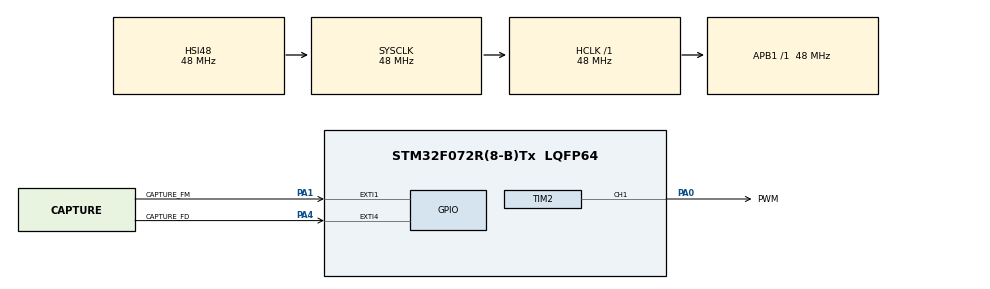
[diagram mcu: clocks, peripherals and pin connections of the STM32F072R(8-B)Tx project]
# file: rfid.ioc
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Mcu.Family=STM32F0
Mcu.Name=STM32F072R(8-B)Tx
Mcu.Package=LQFP64
NVIC.EXTI0_1_IRQn=true\:0\:0\:false\:false\:true\:true
NVIC.EXTI4_15_IRQn=true\:0\:0\:false\:false\:true\:true
NVIC.TIM17_IRQn=true\:0\:0\:false\:false\:true\:true
PA0.GPIO_Label=PWM
PA0.Signal=S_TIM2_CH1_ETR
PA1.GPIO_Label=CAPTURE_FM
PA1.GPIO_ModeDefaultEXTI=GPIO_MODE_IT_RISING
PA1.Signal=GPXTI1
PA4.GPIO_Label=CAPTURE_FD
PA4.GPIO_ModeDefaultEXTI=GPIO_MODE_IT_FALLING
PA4.Signal=GPXTI4
ProjectManager.HeapSize=0x200
ProjectManager.StackSize=0x400
ProjectManager.TargetToolchain=TrueSTUDIO
RCC.AHBFreq_Value=48000000
RCC.APB1Freq_Value=48000000
RCC.APB1TimFreq_Value=48000000
RCC.HCLKFreq_Value=48000000
RCC.SYSCLKFreq_VALUE=48000000
RCC.SYSCLKSource=RCC_SYSCLKSOURCE_HSI48
SH.S_TIM2_CH1_ETR.0=TIM2_CH1,PWM Generation1 CH1
TIM17.Prescaler=48000
TIM2.Channel-PWM\ Generation1\ CH1=TIM_CHANNEL_1
VP_TIM16_VS_ClockSourceINT.Mode=Enable_Timer
VP_TIM17_VS_ClockSourceINT.Mode=Enable_Timer
VP_TIM2_VS_ClockSourceINT.Mode=Internal
VP_TIM7_VS_ClockSourceINT.Mode=Enable_Timer
board=rfid

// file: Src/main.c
/**
  ******************************************************************************
  * @file           : main.c
  * @brief          : Main program body
  ******************************************************************************
  ** This notice applies to any and all portions of this file
  * that are not between comment pairs USER CODE BEGIN and
  * USER CODE END. Other portions of this file, whether
  * inserted by the user or by software development tools
  * are owned by their respective copyright owners.
  *
  * COPYRIGHT(c) 2020 STMicroelectronics
  *
  * Redistribution and use in source and binary forms, with or without modification,
  * are permitted provided that the following conditions are met:
  *   1. Redistributions of source code must retain the above copyright notice,
  *      this list of conditions and the following disclaimer.
  *   2. Redistributions in binary form must reproduce the above copyright notice,
  *      this list of conditions and the following disclaimer in the documentation
  *      and/or other materials provided with the distribution.
  *   3. Neither the name of STMicroelectronics nor the names of its contributors
  *      may be used to endorse or promote products derived from this software
  *      without specific prior written permission.
  *
  * THIS SOFTWARE IS PROVIDED BY THE COPYRIGHT HOLDERS AND CONTRIBUTORS "AS IS"
  * AND ANY EXPRESS OR IMPLIED WARRANTIES, INCLUDING, BUT NOT LIMITED TO, THE
  * IMPLIED WARRANTIES OF MERCHANTABILITY AND FITNESS FOR A PARTICULAR PURPOSE ARE
  * DISCLAIMED. IN NO EVENT SHALL THE COPYRIGHT HOLDER OR CONTRIBUTORS BE LIABLE
  * FOR ANY DIRECT, INDIRECT, INCIDENTAL, SPECIAL, EXEMPLARY, OR CONSEQUENTIAL
  * DAMAGES (INCLUDING, BUT NOT LIMITED TO, PROCUREMENT OF SUBSTITUTE GOODS OR
  * SERVICES; LOSS OF USE, DATA, OR PROFITS; OR BUSINESS INTERRUPTION) HOWEVER
  * CAUSED AND ON ANY THEORY OF LIABILITY, WHETHER IN CONTRACT, STRICT LIABILITY,
  * OR TORT (INCLUDING NEGLIGENCE OR OTHERWISE) ARISING IN ANY WAY OUT OF THE USE
  * OF THIS SOFTWARE, EVEN IF ADVISED OF THE POSSIBILITY OF SUCH DAMAGE.
  *
  ******************************************************************************
  */
#include "main.h"
#include "stm32f0xx_hal.h"

TIM_HandleTypeDef htim2;
TIM_HandleTypeDef htim7;
TIM_HandleTypeDef htim16;
TIM_HandleTypeDef htim17;

/* USER CODE BEGIN PV */
/* Private variables ---------------------------------------------------------*/
volatile int flag_front_montant = 0;
volatile int flag_front_descendant = 0;
volatile int FLAG_TRAME_OK = 0;
volatile int FLAG_HORLOGE_OK = 0;
volatile int COUNT_DONNEES_DEBUT = 0;
volatile int COUNT_DONNEES_FIN = 0;
volatile int NB_US = 0;
volatile int TRAME[64];

// Configurations et calibrations
const volatile int tolerance = 5;

/* USER CODE END PV */

void SystemClock_Config(void);
static void MX_GPIO_Init(void);
static void MX_TIM17_Init(void);
static void MX_TIM16_Init(void);
static void MX_TIM2_Init(void);
static void MX_TIM7_Init(void);
void HAL_TIM_MspPostInit(TIM_HandleTypeDef *htim);

/* USER CODE BEGIN PFP */
/* Private function prototypes -----------------------------------------------*/

/* USER CODE END PFP */

int main(void)
{

  /* MCU Configuration----------------------------------------------------------*/

  /* Reset of all peripherals, Initializes the Flash interface and the Systick. */
  HAL_Init();

  /* Configure the system clock */
  SystemClock_Config();

  /* Initialize all configured peripherals */
  MX_GPIO_Init();
  MX_TIM17_Init();
  MX_TIM16_Init();
  MX_TIM2_Init();
  MX_TIM7_Init();
  /* USER CODE BEGIN 2 */
  HAL_TIM_Base_Start_IT(&htim17);
  /* USER CODE END 2 */

  /* Infinite loop */
  /* USER CODE BEGIN WHILE */
  while (1)
  {
	  if (flag_front_descendant == 1){
		    flag_front_descendant = 0;

			if (FLAG_HORLOGE_OK == 0){
				TIM17->CR1 &= 0;

				TIM17->CR1 |= (1<<0);
				NVIC_EnableIRQ(TIM17_IRQn);
			}
			else if (FLAG_HORLOGE_OK == 1) {

				if (COUNT_DONNEES_DEBUT >= 9){
					TIM17->CR1 &= 0;

					if (512 - tolerance <= NB_US && NB_US >= 512 + tolerance){
						COUNT_DONNEES_DEBUT++;

						// Remplir le tableau de donnees -- 0
						TRAME[COUNT_DONNEES_DEBUT - 10] = 0;

						COUNT_DONNEES_FIN = 0;
					}
					else{
						FLAG_HORLOGE_OK = 0;
					}

					TIM17->CR1 |= (1<<0);
					NVIC_EnableIRQ(TIM17_IRQn);

				}
			}

	  }

	  if (flag_front_montant == 1){
		    flag_front_montant = 0;

			TIM17->CR1 &= 0;

			if (512 - tolerance <= NB_US && NB_US >= 512 + tolerance){
				if (FLAG_HORLOGE_OK == 0){
					FLAG_HORLOGE_OK = 1;
					COUNT_DONNEES_DEBUT++;
				}
				else if(FLAG_HORLOGE_OK == 1){
					COUNT_DONNEES_DEBUT++;

					if (COUNT_DONNEES_DEBUT > 9){
						// Remplir tableau de donnees -- 1
						TRAME[COUNT_DONNEES_DEBUT - 10] = 1;

						COUNT_DONNEES_DEBUT++;
						COUNT_DONNEES_FIN++;

						if (COUNT_DONNEES_FIN == 9){
							// On traite la trame reçu

							FLAG_TRAME_OK = 1;
						}
					}
				}
			}
			else{
				FLAG_HORLOGE_OK = 0;
			}

			TIM17->CR1 |= (1<<0);
			NVIC_EnableIRQ(TIM17_IRQn);
	  }
  /* USER CODE END WHILE */

  }

}

void SystemClock_Config(void)
{

  RCC_OscInitTypeDef RCC_OscInitStruct;
  RCC_ClkInitTypeDef RCC_ClkInitStruct;

    /**Initializes the CPU, AHB and APB busses clocks
    */
  RCC_OscInitStruct.OscillatorType = RCC_OSCILLATORTYPE_HSI48;
  RCC_OscInitStruct.HSI48State = RCC_HSI48_ON;
  RCC_OscInitStruct.PLL.PLLState = RCC_PLL_NONE;
  if (HAL_RCC_OscConfig(&RCC_OscInitStruct) != HAL_OK)
  {
    _Error_Handler(__FILE__, __LINE__);
  }

    /**Initializes the CPU, AHB and APB busses clocks
    */
  RCC_ClkInitStruct.ClockType = RCC_CLOCKTYPE_HCLK|RCC_CLOCKTYPE_SYSCLK
                              |RCC_CLOCKTYPE_PCLK1;
  RCC_ClkInitStruct.SYSCLKSource = RCC_SYSCLKSOURCE_HSI48;
  RCC_ClkInitStruct.AHBCLKDivider = RCC_SYSCLK_DIV1;
  RCC_ClkInitStruct.APB1CLKDivider = RCC_HCLK_DIV1;

  if (HAL_RCC_ClockConfig(&RCC_ClkInitStruct, FLASH_LATENCY_1) != HAL_OK)
  {
    _Error_Handler(__FILE__, __LINE__);
  }

    /**Configure the Systick interrupt time
    */
  HAL_SYSTICK_Config(HAL_RCC_GetHCLKFreq()/1000);

    /**Configure the Systick
    */
  HAL_SYSTICK_CLKSourceConfig(SYSTICK_CLKSOURCE_HCLK);

  /* SysTick_IRQn interrupt configuration */
  HAL_NVIC_SetPriority(SysTick_IRQn, 0, 0);
}

/* TIM2 init function */
static void MX_TIM2_Init(void)
{

  TIM_ClockConfigTypeDef sClockSourceConfig;
  TIM_MasterConfigTypeDef sMasterConfig;
  TIM_OC_InitTypeDef sConfigOC;

  htim2.Instance = TIM2;
  htim2.Init.Prescaler = 0;
  htim2.Init.CounterMode = TIM_COUNTERMODE_UP;
  htim2.Init.Period = 0;
  htim2.Init.ClockDivision = TIM_CLOCKDIVISION_DIV1;
  htim2.Init.AutoReloadPreload = TIM_AUTORELOAD_PRELOAD_DISABLE;
  if (HAL_TIM_Base_Init(&htim2) != HAL_OK)
  {
    _Error_Handler(__FILE__, __LINE__);
  }

  sClockSourceConfig.ClockSource = TIM_CLOCKSOURCE_INTERNAL;
  if (HAL_TIM_ConfigClockSource(&htim2, &sClockSourceConfig) != HAL_OK)
  {
    _Error_Handler(__FILE__, __LINE__);
  }

  if (HAL_TIM_PWM_Init(&htim2) != HAL_OK)
  {
    _Error_Handler(__FILE__, __LINE__);
  }

  sMasterConfig.MasterOutputTrigger = TIM_TRGO_RESET;
  sMasterConfig.MasterSlaveMode = TIM_MASTERSLAVEMODE_DISABLE;
  if (HAL_TIMEx_MasterConfigSynchronization(&htim2, &sMasterConfig) != HAL_OK)
  {
    _Error_Handler(__FILE__, __LINE__);
  }

  sConfigOC.OCMode = TIM_OCMODE_PWM1;
  sConfigOC.Pulse = 0;
  sConfigOC.OCPolarity = TIM_OCPOLARITY_HIGH;
  sConfigOC.OCFastMode = TIM_OCFAST_DISABLE;
  if (HAL_TIM_PWM_ConfigChannel(&htim2, &sConfigOC, TIM_CHANNEL_1) != HAL_OK)
  {
    _Error_Handler(__FILE__, __LINE__);
  }

  HAL_TIM_MspPostInit(&htim2);

}

/* TIM7 init function */
static void MX_TIM7_Init(void)
{

  TIM_MasterConfigTypeDef sMasterConfig;

  htim7.Instance = TIM7;
  htim7.Init.Prescaler = 0;
  htim7.Init.CounterMode = TIM_COUNTERMODE_UP;
  htim7.Init.Period = 0;
  htim7.Init.AutoReloadPreload = TIM_AUTORELOAD_PRELOAD_DISABLE;
  if (HAL_TIM_Base_Init(&htim7) != HAL_OK)
  {
    _Error_Handler(__FILE__, __LINE__);
  }

  sMasterConfig.MasterOutputTrigger = TIM_TRGO_RESET;
  sMasterConfig.MasterSlaveMode = TIM_MASTERSLAVEMODE_DISABLE;
  if (HAL_TIMEx_MasterConfigSynchronization(&htim7, &sMasterConfig) != HAL_OK)
  {
    _Error_Handler(__FILE__, __LINE__);
  }

}

/* TIM16 init function */
static void MX_TIM16_Init(void)
{

  htim16.Instance = TIM16;
  htim16.Init.Prescaler = 0;
  htim16.Init.CounterMode = TIM_COUNTERMODE_UP;
  htim16.Init.Period = 0;
  htim16.Init.ClockDivision = TIM_CLOCKDIVISION_DIV1;
  htim16.Init.RepetitionCounter = 0;
  htim16.Init.AutoReloadPreload = TIM_AUTORELOAD_PRELOAD_DISABLE;
  if (HAL_TIM_Base_Init(&htim16) != HAL_OK)
  {
    _Error_Handler(__FILE__, __LINE__);
  }

}

/* TIM17 init function */
static void MX_TIM17_Init(void)
{

  htim17.Instance = TIM17;
  htim17.Init.Prescaler = 48000;
  htim17.Init.CounterMode = TIM_COUNTERMODE_UP;
  htim17.Init.Period = 0;
  htim17.Init.ClockDivision = TIM_CLOCKDIVISION_DIV1;
  htim17.Init.RepetitionCounter = 0;
  htim17.Init.AutoReloadPreload = TIM_AUTORELOAD_PRELOAD_DISABLE;
  if (HAL_TIM_Base_Init(&htim17) != HAL_OK)
  {
    _Error_Handler(__FILE__, __LINE__);
  }

}

/** Configure pins as
        * Analog
        * Input
        * Output
        * EVENT_OUT
        * EXTI
*/
static void MX_GPIO_Init(void)
{

  GPIO_InitTypeDef GPIO_InitStruct;

  /* GPIO Ports Clock Enable */
  __HAL_RCC_GPIOA_CLK_ENABLE();

  /*Configure GPIO pin : CAPTURE_FM_Pin */
  GPIO_InitStruct.Pin = CAPTURE_FM_Pin;
  GPIO_InitStruct.Mode = GPIO_MODE_IT_RISING;
  GPIO_InitStruct.Pull = GPIO_NOPULL;
  HAL_GPIO_Init(CAPTURE_FM_GPIO_Port, &GPIO_InitStruct);

  /*Configure GPIO pin : CAPTURE_FD_Pin */
  GPIO_InitStruct.Pin = CAPTURE_FD_Pin;
  GPIO_InitStruct.Mode = GPIO_MODE_IT_FALLING;
  GPIO_InitStruct.Pull = GPIO_NOPULL;
  HAL_GPIO_Init(CAPTURE_FD_GPIO_Port, &GPIO_InitStruct);

  /* EXTI interrupt init*/
  HAL_NVIC_SetPriority(EXTI0_1_IRQn, 0, 0);
  HAL_NVIC_EnableIRQ(EXTI0_1_IRQn);

  HAL_NVIC_SetPriority(EXTI4_15_IRQn, 0, 0);
  HAL_NVIC_EnableIRQ(EXTI4_15_IRQn);

}

/* USER CODE BEGIN 4 */
void HAL_GPIO_EXTI_Callback(uint16_t GPIO_Pin)
{

	// Entree Capture RFID Front Descendant
	if(GPIO_Pin == GPIO_PIN_4)
	{
		flag_front_descendant = 1;
	}

	// Entree Capture RFID Front Montant
	if(GPIO_Pin == GPIO_PIN_1)
	{
		flag_front_montant = 1;
	}

}

void HAL_TIM_PeriodElapsedCallback(TIM_HandleTypeDef *htim)
{

	if (htim->Instance == TIM17)
	{
		// Incrementation du nombre de micro_seconde
		NB_US++;
	}
}
/* USER CODE END 4 */

void _Error_Handler(char *file, int line)
{
  while(1)
  {
  }
}

/************************ (C) COPYRIGHT STMicroelectronics *****END OF FILE****/
